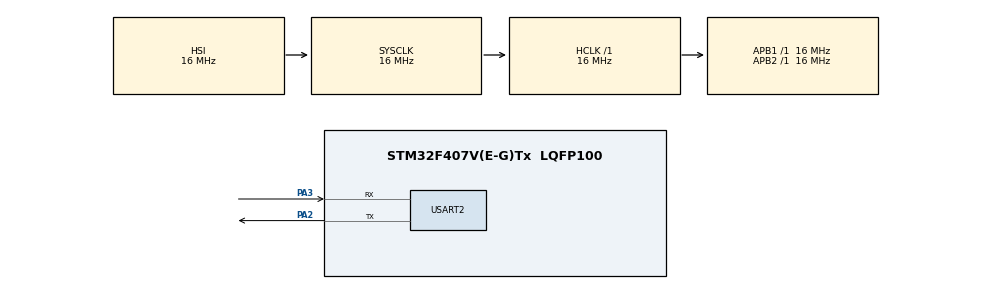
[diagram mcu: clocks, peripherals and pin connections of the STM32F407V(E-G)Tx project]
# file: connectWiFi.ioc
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Mcu.Family=STM32F4
RCC.VCOOutputFreq_Value=192000000
RCC.APB2Freq_Value=16000000
RCC.CortexFreq_Value=16000000
TIM6.Prescaler=50-1
TIM6.Period=0xffff-1
VP_TIM6_VS_ClockSourceINT.Mode=Enable_Timer
Mcu.Name=STM32F407V(E-G)Tx
PA2.Signal=USART2_TX
RCC.SYSCLKFreq_VALUE=16000000
Mcu.Package=LQFP100
ProjectManager.StackSize=0x400
USART2.VirtualMode=VM_ASYNC
PA3.Mode=Asynchronous
ProjectManager.HeapSize=0x200
ProjectManager.TargetToolchain=STM32CubeIDE
RCC.HSI_VALUE=16000000
NVIC.PriorityGroup=NVIC_PRIORITYGROUP_4
PA2.Mode=Asynchronous
RCC.APB1Freq_Value=16000000
RCC.LSE_VALUE=32768
RCC.AHBFreq_Value=16000000
RCC.HSE_VALUE=25000000
PA3.Signal=USART2_RX
board=custom

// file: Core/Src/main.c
/* USER CODE BEGIN Header */
/**
  ******************************************************************************
  * @file           : main.c
  * @brief          : Main program body
  ******************************************************************************
  * @attention
  *
  * <h2><center>&copy; Copyright (c) 2022 STMicroelectronics.
  * All rights reserved.</center></h2>
  *
  * This software component is licensed by ST under BSD 3-Clause license,
  * the "License"; You may not use this file except in compliance with the
  * License. You may obtain a copy of the License at:
  *                        opensource.org/licenses/BSD-3-Clause
  *
  ******************************************************************************
  */
/* USER CODE END Header */
#include "main.h"
#include <stdio.h>

TIM_HandleTypeDef htim6;

UART_HandleTypeDef huart2;

/* USER CODE BEGIN PV */
void bufclr (char *buf)
{
	int len = strlen (buf);
	for (int i=0; i<len; i++) buf[i] = '\0';
}
/* USER CODE END PV */

void SystemClock_Config(void);
static void MX_GPIO_Init(void);
static void MX_TIM6_Init(void);
static void MX_USART2_UART_Init(void);

int main(void)
{

  /* MCU Configuration--------------------------------------------------------*/

  /* Reset of all peripherals, Initializes the Flash interface and the Systick. */
  HAL_Init();

  /* Configure the system clock */
  SystemClock_Config();

  /* Initialize all configured peripherals */
  MX_GPIO_Init();
  MX_TIM6_Init();
  MX_USART2_UART_Init();
  /* USER CODE BEGIN 2 */
  char data[80];
// estabelecendo a conexao
  HAL_UART_Transmit(&huart2,"AT+RST\r\n",8, HAL_MAX_DELAY);
  HAL_Delay(1000);
  HAL_UART_Transmit(&huart2,"AT\r\n",4, HAL_MAX_DELAY);
  HAL_Delay(1000);
  HAL_UART_Transmit(&huart2,"AT+CWMODE=1\r\n",13, HAL_MAX_DELAY);
  HAL_Delay(1000);
  sprintf (data, "AT+CWJAP=\"%s\",\"%s\"\r\n", "Nicolle", "nicolle789");
  //sprintf (data, "AT+CWJAP=\"%s\"\r\n", "IME-Servicos");
  HAL_UART_Transmit(&huart2,data,strlen(data), HAL_MAX_DELAY);
  HAL_Delay(1000);
  HAL_UART_Transmit(&huart2,"AT+CIPMUX=0\r\n",13, HAL_MAX_DELAY);
  HAL_Delay(1000);
  /* USER CODE END 2 */
	  uint16_t value[2];
	  value[0] = 20; //temp
	  value[1] = 30; //umid
  /* Infinite loop */
  while (1)
  {
	  value[0] = value[0]+1; //temp
	  value[1] = value[1]+2; //umid

	  	char local_buf[500] = {0};
	  	char local_buf2[30] = {0};
	  	char local_buf3[50] = {0};
	  	char field_buf[200] = {0};
		sprintf (local_buf3, "AT+CIPSTART=\"TCP\",\"184.106.153.149\",80\r\n");
	   // HAL_Delay(3000);

	    HAL_UART_Transmit(&huart2,(uint8_t*)"AT+CIPSTART=\"TCP\",\"184.106.153.149\",80\r\n",sizeof("AT+CIPSTART=\"TCP\",\"184.106.153.149\",80\r\n")-1, HAL_MAX_DELAY);

	    HAL_Delay(500);

	  	sprintf (local_buf, "GET /update?api_key=D5ESDZQZA2Y2UY2C");
	  	for (int i=0; i<2; i++)
	  	{
	  		sprintf(field_buf, "&field%d=%u",i+1, value[i]);
	  		strcat(local_buf, field_buf);
	  	}

	  	strcat(local_buf, "\r\n");
	  	int len = strlen(local_buf);

	  	sprintf (local_buf2, "AT+CIPSEND=%d\r\n", len);
	    HAL_UART_Transmit(&huart2,local_buf2,strlen(local_buf2), HAL_MAX_DELAY);
	    HAL_Delay(500);
	    HAL_UART_Transmit(&huart2,local_buf,strlen(local_buf), HAL_MAX_DELAY);
	    HAL_Delay(500);

	  	bufclr(local_buf);
	  	bufclr(local_buf2);
	    HAL_Delay(15000);//delay necessario para atualizar

  }
}

void SystemClock_Config(void)
{
  RCC_OscInitTypeDef RCC_OscInitStruct = {0};
  RCC_ClkInitTypeDef RCC_ClkInitStruct = {0};

  /** Configure the main internal regulator output voltage
  */
  __HAL_RCC_PWR_CLK_ENABLE();
  __HAL_PWR_VOLTAGESCALING_CONFIG(PWR_REGULATOR_VOLTAGE_SCALE1);
  /** Initializes the RCC Oscillators according to the specified parameters
  * in the RCC_OscInitTypeDef structure.
  */
  RCC_OscInitStruct.OscillatorType = RCC_OSCILLATORTYPE_HSI;
  RCC_OscInitStruct.HSIState = RCC_HSI_ON;
  RCC_OscInitStruct.HSICalibrationValue = RCC_HSICALIBRATION_DEFAULT;
  RCC_OscInitStruct.PLL.PLLState = RCC_PLL_NONE;
  if (HAL_RCC_OscConfig(&RCC_OscInitStruct) != HAL_OK)
  {
    Error_Handler();
  }
  /** Initializes the CPU, AHB and APB buses clocks
  */
  RCC_ClkInitStruct.ClockType = RCC_CLOCKTYPE_HCLK|RCC_CLOCKTYPE_SYSCLK
                              |RCC_CLOCKTYPE_PCLK1|RCC_CLOCKTYPE_PCLK2;
  RCC_ClkInitStruct.SYSCLKSource = RCC_SYSCLKSOURCE_HSI;
  RCC_ClkInitStruct.AHBCLKDivider = RCC_SYSCLK_DIV1;
  RCC_ClkInitStruct.APB1CLKDivider = RCC_HCLK_DIV1;
  RCC_ClkInitStruct.APB2CLKDivider = RCC_HCLK_DIV1;

  if (HAL_RCC_ClockConfig(&RCC_ClkInitStruct, FLASH_LATENCY_0) != HAL_OK)
  {
    Error_Handler();
  }
}

static void MX_TIM6_Init(void)
{

  TIM_MasterConfigTypeDef sMasterConfig = {0};

  htim6.Instance = TIM6;
  htim6.Init.Prescaler = 50-1;
  htim6.Init.CounterMode = TIM_COUNTERMODE_UP;
  htim6.Init.Period = 0xffff-1;
  htim6.Init.AutoReloadPreload = TIM_AUTORELOAD_PRELOAD_DISABLE;
  if (HAL_TIM_Base_Init(&htim6) != HAL_OK)
  {
    Error_Handler();
  }
  sMasterConfig.MasterOutputTrigger = TIM_TRGO_RESET;
  sMasterConfig.MasterSlaveMode = TIM_MASTERSLAVEMODE_DISABLE;
  if (HAL_TIMEx_MasterConfigSynchronization(&htim6, &sMasterConfig) != HAL_OK)
  {
    Error_Handler();
  }

}

static void MX_USART2_UART_Init(void)
{

  huart2.Instance = USART2;
  huart2.Init.BaudRate = 115200;
  huart2.Init.WordLength = UART_WORDLENGTH_8B;
  huart2.Init.StopBits = UART_STOPBITS_1;
  huart2.Init.Parity = UART_PARITY_NONE;
  huart2.Init.Mode = UART_MODE_TX_RX;
  huart2.Init.HwFlowCtl = UART_HWCONTROL_NONE;
  huart2.Init.OverSampling = UART_OVERSAMPLING_16;
  if (HAL_UART_Init(&huart2) != HAL_OK)
  {
    Error_Handler();
  }

}

static void MX_GPIO_Init(void)
{

  /* GPIO Ports Clock Enable */
  __HAL_RCC_GPIOA_CLK_ENABLE();

}

void Error_Handler(void)
{
  __disable_irq();
  while (1)
  {
  }
}

/************************ (C) COPYRIGHT STMicroelectronics *****END OF FILE****/
